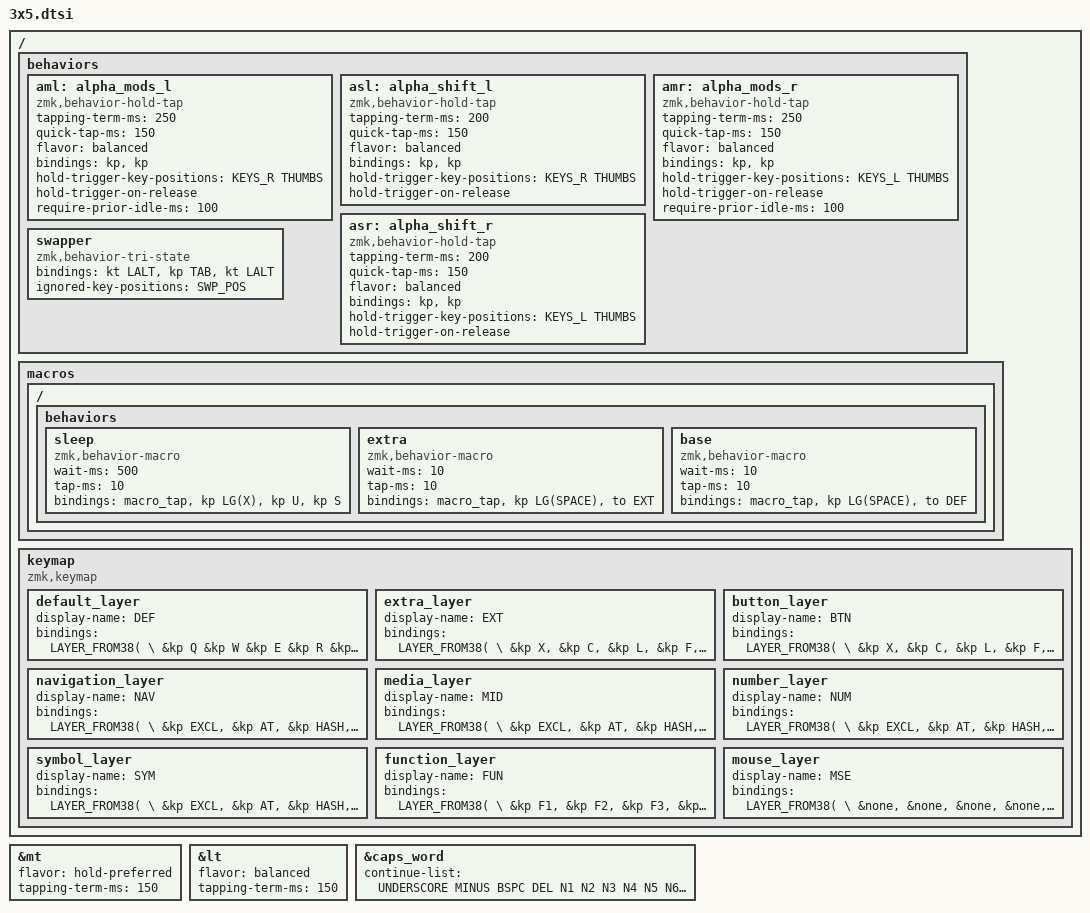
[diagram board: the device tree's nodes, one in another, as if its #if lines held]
#include <behaviors.dtsi>
#include <dt-bindings/zmk/keys.h>
#include <dt-bindings/zmk/bt.h>
#include <dt-bindings/zmk/outputs.h>
#ifdef EXTERNAL_POWER
#    include <dt-bindings/zmk/ext_power.h>
#endif

// Layer aliases
#define DEF 0
#define EXT 1
#define BTN 2
#define NAV 3
#define MID 4
#define NUM 5
#define SYM 6
#define FUN 7
#define MSE 8

// Dongle mode. keyboardname.keymap include #define DONGLE_MODE
#ifdef DONGLE_MODE
#    define mid0    &kp LC(Y)
#    define mid1    &kp LC(V)
#    define mid2    &kp LC(C)
#    define mid3    &kp LC(X)
#    define mid4    &kp LC(Z)
#    define mid5    &none
#    define mid6    &none
#else
#    define mid0    &bt BT_SEL 0
#    define mid1    &bt BT_SEL 1
#    define mid2    &bt BT_SEL 2
#    define mid3    &bt BT_SEL 3
#    define mid4    &bt BT_SEL 4
#    define mid5    &bt BT_CLR
#    define mid6    &bt BT_CLR_ALL
#endif

// Desktop and tab navigation shortcuts
#define D_LT   LC(LG(LEFT))
#define D_RT   LC(LG(RIGHT))
#define TAB_RT LC(TAB)
#define TAB_LT LC(LS(TAB))

// Extra key bindings
#define SWP_POS LB2

#include "combos.dtsi"

#ifdef MOUSE_KEYS
#    include "mouse.dtsi"
#    define MS_ACT(key) &lt MSE key
#else
#    define MS_ACT(key) &kp key
#endif

&mt {
    flavor = "hold-preferred";
    tapping-term-ms = <150>;
};

&lt {
    flavor = "balanced";
    tapping-term-ms = <150>;
};

&caps_word {
    continue-list = <UNDERSCORE MINUS BSPC DEL N1 N2 N3 N4 N5 N6 N7 N8 N9 N0>;
};

/ {
    behaviors {
        aml: alpha_mods_l {
            compatible = "zmk,behavior-hold-tap";
            #binding-cells = <2>;
            tapping-term-ms = <250>;
            quick-tap-ms = <150>;
            flavor = "balanced";
            bindings = <&kp>, <&kp>;
            hold-trigger-key-positions = <KEYS_R THUMBS>;
            hold-trigger-on-release;
            require-prior-idle-ms = <100>;
        };
        asl: alpha_shift_l {
            compatible = "zmk,behavior-hold-tap";
            #binding-cells = <2>;
            tapping-term-ms = <200>;
            quick-tap-ms = <150>;
            flavor = "balanced";
            bindings = <&kp>, <&kp>;
            hold-trigger-key-positions = <KEYS_R THUMBS>;
            hold-trigger-on-release;
        };
        amr: alpha_mods_r {
            compatible = "zmk,behavior-hold-tap";
            #binding-cells = <2>;
            tapping-term-ms = <250>;
            quick-tap-ms = <150>;
            flavor = "balanced";
            bindings = <&kp>, <&kp>;
            hold-trigger-key-positions = <KEYS_L THUMBS>;
            hold-trigger-on-release;
            require-prior-idle-ms = <100>;
        };
        asr: alpha_shift_r {
            compatible = "zmk,behavior-hold-tap";
            #binding-cells = <2>;
            tapping-term-ms = <200>;
            quick-tap-ms = <150>;
            flavor = "balanced";
            bindings = <&kp>, <&kp>;
            hold-trigger-key-positions = <KEYS_L THUMBS>;
            hold-trigger-on-release;
        };

        // Swapper for smart alt+tab
        swapper: swapper {
            compatible = "zmk,behavior-tri-state";
            #binding-cells = <0>;
            bindings = <&kt LALT>, <&kp TAB>, <&kt LALT>;
            ignored-key-positions = <SWP_POS>;    //<SWP_POS>; &kp LS(TAB) position
        };
    };

    macros {
        ZMK_MACRO(sleep,
            wait-ms = <500>;
            tap-ms = <10>;
            bindings
                = <&macro_tap &kp LG(X) &kp U &kp S>;
        )
// 시간및언어>언어및지역>기본설정언어 한국어, 영어(미국) 2가지가 있을 때 작동
        ZMK_MACRO(extra,
            wait-ms = <10>;
            tap-ms = <10>;
            bindings
                = <&macro_tap &kp LG(SPACE) &to EXT>;    // BRD->EXT로바꿔야함
        )
        ZMK_MACRO(base,
            wait-ms = <10>;
            tap-ms = <10>;
            bindings
                = <&macro_tap &kp LG(SPACE) &to DEF>;
        )
    };

    keymap {
        compatible = "zmk,keymap";

        default_layer {
            display-name = "DEF";
            bindings = <LAYER_FROM38( \
//     ╭─────────────┬─────────────┬─────────────┬─────────────┬─────────────╮   ╭─────────────┬─────────────┬─────────────┬─────────────┬─────────────╮
        &kp Q         &kp W         &kp E         &kp R         &kp T             &kp Y         &kp U         &kp I         &kp O         &kp P            
        &aml LGUI A   &aml LALT S   &aml LCTRL D  &asl LSHFT F  &kp G             &kp H         &asr LSHFT J  &amr LCTRL K  &amr LALT L   &aml LGUI SQT   
&kp ESC &lt BTN Z     &kp X         &kp C         &kp V         &lt MID B         &lt FUN N     &kp M         &amr RCTRL COMMA &amr RALT DOT &lt BTN SLASH &kp RET
                                    &lt MID ESC      &lt NAV SPACE MS_ACT(TAB )      &lt SYM RET   &lt NUM BSPC  &lt FUN DEL
//                                               ╰─────────────┴─────────────╯   ╰─────────────┴─────────────╯
            )>;
        };

        extra_layer {
            display-name = "EXT";
            bindings = <LAYER_FROM38( \
// ╭─────────────┬─────────────┬─────────────┬─────────────┬─────────────╮   ╭─────────────┬─────────────┬─────────────┬─────────────┬─────────────╮
     &kp X,        &kp C,        &kp L,        &kp F,        &kp B,            &kp J,        &kp Y,        &kp O,        &kp U,        &kp SQT,      \
//, ├─────────────┼─────────────┼─────────────┼─────────────┼─────────────┤   ├─────────────┼─────────────┼─────────────┼─────────────┼─────────────┤
     &aml LCTRL R, &aml LGUI S,  &aml LALT N,  &asl LSHFT T, &kp P,            &kp K,        &asr RSHFT H, &amr RALT E,  &amr RGUI I,  &amr RCTRL A, \
// ├─────────────┼─────────────┼─────────────┼─────────────┼─────────────┤   ├─────────────┼─────────────┼─────────────┼─────────────┼─────────────┤
     &none,        &kp W,        &kp M,        &kp C,    &none,            &none,        &kp D,        &kp COMMA,    &kp DOT,      &none, &none, &none,        \
//, ╰─────────────┴─────────────┴─────────────┼─────────────┼─────────────┤   ├─────────────┼─────────────┼─────────────┴─────────────┴─────────────╯
                                 &mt LGUI TAB, &mt LCTRL ESC, &lt NAV SPACE,   &lt SYM BSPC, &mt RSHFT RET, &mt RALT DEL                             \
//                             ╰─────────────┴─────────────┴─────────────╯   ╰─────────────┴─────────────┴─────────────╯
            )>;
        };

        button_layer {
            display-name = "BTN";
            bindings = <LAYER_FROM38( \
// ╭─────────────┬─────────────┬─────────────┬─────────────┬─────────────╮   ╭─────────────┬─────────────┬─────────────┬─────────────┬─────────────╮
     &kp X,        &kp C,        &kp L,        &kp F,        &kp B,            &kp J,        &kp Y,        &kp O,        &kp U,        &kp SQT,      \
//, ├─────────────┼─────────────┼─────────────┼─────────────┼─────────────┤   ├─────────────┼─────────────┼─────────────┼─────────────┼─────────────┤
     &aml LCTRL R, &aml LGUI S,  &aml LALT N,  &asl LSHFT T, &kp P,            &kp K,        &asr RSHFT H, &amr RALT E,  &amr RGUI I,  &amr RCTRL A, \
// ├─────────────┼─────────────┼─────────────┼─────────────┼─────────────┤   ├─────────────┼─────────────┼─────────────┼─────────────┼─────────────┤
     &none,        &kp W,        &kp M,        &kp C,    &none,            &none,        &kp D,        &kp COMMA,    &kp DOT,      &none, &none, &none,        \
//, ╰─────────────┴─────────────┴─────────────┼─────────────┼─────────────┤   ├─────────────┼─────────────┼─────────────┴─────────────┴─────────────╯
                                 &mt LGUI TAB, &mt LCTRL ESC, &lt NAV SPACE,   &lt SYM BSPC, &mt RSHFT RET, &mt RALT DEL                             \
//                             ╰─────────────┴─────────────┴─────────────╯   ╰─────────────┴─────────────┴─────────────╯
            )>;
        };

        navigation_layer {
            display-name = "NAV";
            bindings = <LAYER_FROM38( \
// ╭─────────────┬─────────────┬─────────────┬─────────────┬─────────────╮   ╭─────────────┬─────────────┬─────────────┬─────────────┬─────────────╮
     &kp EXCL,     &kp AT,       &kp HASH,     &kp DLLR,     &kp PRCNT,        &kp SLASH,    &kp N7,       &kp N8,       &kp N9,       &kp COMMA, \
// ├─────────────┼─────────────┼─────────────┼─────────────┼─────────────┤   ├─────────────┼─────────────┼─────────────┼─────────────┼─────────────┤
     &kp PLUS,     &kp EQUAL,    &kp UNDER,    &kp MINUS,    &kp CARET,        &kp N0,       &kp N4,       &kp N5,       &kp N6,       &kp DOT,   \
// ├─────────────┼─────────────┼─────────────┼─────────────┼─────────────┤   ├─────────────┼─────────────┼─────────────┼─────────────┼─────────────┤
     &none,        &none,      &kp STAR,     &kp AMPS,     &none,            &kp SEMI,     &kp N1,       &kp N2,       &kp N3,       &kp SLASH, &none, &none, \
// ╰─────────────┴─────────────┴─────────────┼─────────────┼─────────────┤   ├─────────────┼─────────────┼─────────────┴─────────────┴─────────────╯
                                 &kp LGUI,     &kp BSPC,     &trans,           &trans,       &none,        &kp RALT                               \
//                             ╰─────────────┴─────────────┴─────────────╯   ╰─────────────┴─────────────┴─────────────╯
            )>;
        };

        media_layer {
            display-name = "MID";
            bindings = <LAYER_FROM38( \
// ╭─────────────┬─────────────┬─────────────┬─────────────┬─────────────╮   ╭─────────────┬─────────────┬─────────────┬─────────────┬─────────────╮
     &kp EXCL,     &kp AT,       &kp HASH,     &kp DLLR,     &kp PRCNT,        &kp SLASH,    &kp N7,       &kp N8,       &kp N9,       &kp COMMA, \
// ├─────────────┼─────────────┼─────────────┼─────────────┼─────────────┤   ├─────────────┼─────────────┼─────────────┼─────────────┼─────────────┤
     &kp PLUS,     &kp EQUAL,    &kp UNDER,    &kp MINUS,    &kp CARET,        &kp N0,       &kp N4,       &kp N5,       &kp N6,       &kp DOT,   \
// ├─────────────┼─────────────┼─────────────┼─────────────┼─────────────┤   ├─────────────┼─────────────┼─────────────┼─────────────┼─────────────┤
     &none,        &none,      &kp STAR,     &kp AMPS,     &none,            &kp SEMI,     &kp N1,       &kp N2,       &kp N3,       &kp SLASH, &none, &none, \
// ╰─────────────┴─────────────┴─────────────┼─────────────┼─────────────┤   ├─────────────┼─────────────┼─────────────┴─────────────┴─────────────╯
                                 &kp LGUI,     &kp BSPC,     &trans,           &trans,       &none,        &kp RALT                               \
//                             ╰─────────────┴─────────────┴─────────────╯   ╰─────────────┴─────────────┴─────────────╯
            )>;
        };

        number_layer {
            display-name = "NUM";
            bindings = <LAYER_FROM38( \
// ╭─────────────┬─────────────┬─────────────┬─────────────┬─────────────╮   ╭─────────────┬─────────────┬─────────────┬─────────────┬─────────────╮
     &kp EXCL,     &kp AT,       &kp HASH,     &kp DLLR,     &kp PRCNT,        &kp SLASH,    &kp N7,       &kp N8,       &kp N9,       &kp COMMA, \
// ├─────────────┼─────────────┼─────────────┼─────────────┼─────────────┤   ├─────────────┼─────────────┼─────────────┼─────────────┼─────────────┤
     &kp PLUS,     &kp EQUAL,    &kp UNDER,    &kp MINUS,    &kp CARET,        &kp N0,       &kp N4,       &kp N5,       &kp N6,       &kp DOT,   \
// ├─────────────┼─────────────┼─────────────┼─────────────┼─────────────┤   ├─────────────┼─────────────┼─────────────┼─────────────┼─────────────┤
     &none,        &none,      &kp STAR,     &kp AMPS,     &none,            &kp SEMI,     &kp N1,       &kp N2,       &kp N3,       &kp SLASH, &none, &none, \
// ╰─────────────┴─────────────┴─────────────┼─────────────┼─────────────┤   ├─────────────┼─────────────┼─────────────┴─────────────┴─────────────╯
                                 &kp LGUI,     &kp BSPC,     &trans,           &trans,       &none,        &kp RALT                               \
//                             ╰─────────────┴─────────────┴─────────────╯   ╰─────────────┴─────────────┴─────────────╯
            )>;
        };

        symbol_layer {
            display-name = "SYM";
            bindings = <LAYER_FROM38( \
// ╭─────────────┬─────────────┬─────────────┬─────────────┬─────────────╮   ╭─────────────┬─────────────┬─────────────┬─────────────┬─────────────╮
     &kp EXCL,     &kp AT,       &kp HASH,     &kp DLLR,     &kp PRCNT,        &kp SLASH,    &kp N7,       &kp N8,       &kp N9,       &kp COMMA, \
// ├─────────────┼─────────────┼─────────────┼─────────────┼─────────────┤   ├─────────────┼─────────────┼─────────────┼─────────────┼─────────────┤
     &kp PLUS,     &kp EQUAL,    &kp UNDER,    &kp MINUS,    &kp CARET,        &kp N0,       &kp N4,       &kp N5,       &kp N6,       &kp DOT,   \
// ├─────────────┼─────────────┼─────────────┼─────────────┼─────────────┤   ├─────────────┼─────────────┼─────────────┼─────────────┼─────────────┤
     &none,        &none,      &kp STAR,     &kp AMPS,     &none,            &kp SEMI,     &kp N1,       &kp N2,       &kp N3,       &kp SLASH, &none, &none, \
// ╰─────────────┴─────────────┴─────────────┼─────────────┼─────────────┤   ├─────────────┼─────────────┼─────────────┴─────────────┴─────────────╯
                                 &kp LGUI,     &kp BSPC,     &trans,           &trans,       &none,        &kp RALT                               \
//                             ╰─────────────┴─────────────┴─────────────╯   ╰─────────────┴─────────────┴─────────────╯
            )>;
        };

        function_layer {
            display-name = "FUN";
            bindings = <LAYER_FROM38( \
// ╭─────────────┬─────────────┬─────────────┬─────────────┬─────────────╮   ╭─────────────┬─────────────┬─────────────┬─────────────┬─────────────╮
     &kp F1,       &kp F2,       &kp F3,       &kp F4,       &kp F5,           &out OUT_USB, &out OUT_BLE, &none,      &none,      &none,      \
// ├─────────────┼─────────────┼─────────────┼─────────────┼─────────────┤   ├─────────────┼─────────────┼─────────────┼─────────────┼─────────────┤
     &kp F6,       &kp F7,       &kp F8,       &kp F9,       &kp F10,          &bt BT_SEL 0, &bt BT_SEL 1, &bt BT_SEL 2, &bt BT_SEL 3, &bt BT_SEL 4, \
// ├─────────────┼─────────────┼─────────────┼─────────────┼─────────────┤   ├─────────────┼─────────────┼─────────────┼─────────────┼─────────────┤
     &none,        &kp D_LT,     &kp D_RT,     &kp F11,      &kp F12,          &none,        &kp CAPS,     &kp CAPS,    &kp CAPS,    &none, &none, &none,        \
// ╰─────────────┴─────────────┴─────────────┼─────────────┼─────────────┤   ├─────────────┼─────────────┼─────────────┴─────────────┴─────────────╯
                                 &none,        &none,  &none,           &none,       &none,  &none                                     \
//                             ╰─────────────┴─────────────┴─────────────╯   ╰─────────────┴─────────────┴─────────────╯
            )>;
        };

#ifdef MOUSE_KEYS
        mouse_layer {
            display-name = "MSE";
            bindings = <LAYER_FROM38( \
// ╭─────────────┬─────────────┬─────────────┬─────────────┬─────────────╮   ╭─────────────┬─────────────┬─────────────┬─────────────┬─────────────╮
     &none,        &none,        &none,        &none,        &none,          &msc SCRL_LEFT, &msc SCRL_DOWN, &mmv MOVE_UP, &msc SCRL_UP, &msc SCRL_RIGHT, \
// ├─────────────┼─────────────┼─────────────┼─────────────┼─────────────┤   ├─────────────┼─────────────┼─────────────┼─────────────┼─────────────┤
     &kp LCTRL,    &kp LGUI,     &kp LALT,     &kp LSHFT,    &none,            &mkp RCLK,  &mmv MOVE_LEFT, &mmv MOVE_DOWN, &mmv MOVE_RIGHT, &none,         \
// ├─────────────┼─────────────┼─────────────┼─────────────┼─────────────┤   ├─────────────┼─────────────┼─────────────┼─────────────┼─────────────┤
     &none,        &none,        &none,        &none,        &none,            &none,        &mkp MB4,     &mkp MCLK,    &mkp MB5,     &none, &none, &none,           \
// ╰─────────────┴─────────────┴─────────────┼─────────────┼─────────────┤   ├─────────────┼─────────────┼─────────────┴─────────────┴─────────────╯
                                 &none,        &none,        &none,            &mkp LCLK,    &mkp RCLK,    &none                                        \
//                             ╰─────────────┴─────────────┴─────────────╯   ╰─────────────┴─────────────┴─────────────╯
            )>;
        };
#endif
    };
};
